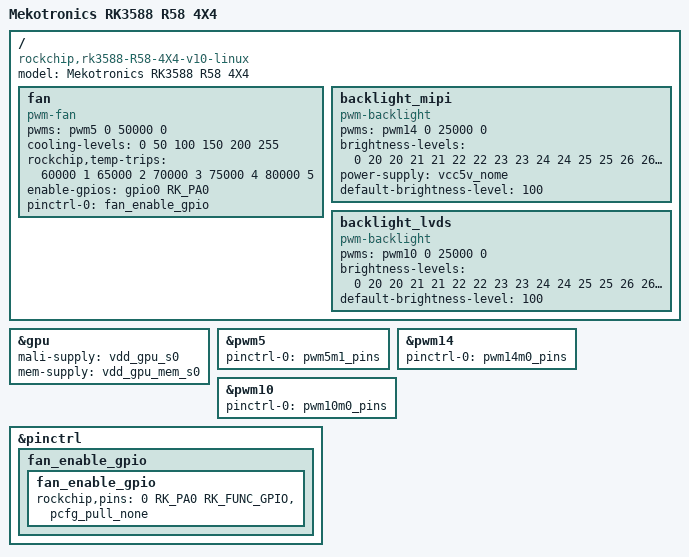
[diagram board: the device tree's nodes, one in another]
// SPDX-License-Identifier: (GPL-2.0+ OR MIT)
/*
 * Copyright (c) 2021 Rockchip Electronics Co., Ltd.
 *
 */

/dts-v1/;

#include "rk3588-blueberry-r58-4X4.dtsi"
#include "rk3588-linux.dtsi"
#include "rk3588-blueberry-r58-4X4-LT6911UXE-1.dtsi"
#include "rk3588-blueberry-r58-4X4-LT6911UXE-2.dtsi"
#include "rk3588-blueberry-r58-4X4-LT6911UXE-3.dtsi"

/ {
	model = "Mekotronics RK3588 R58 4X4";
	compatible = "rockchip,rk3588-R58-4X4-v10-linux", "rockchip,rk3588";
	/delete-node/ chosen;

	fan{
		compatible = "pwm-fan";
		#cooling-cells = <2>;
		pwms = <&pwm5 0 50000 0>;
		cooling-levels = <0 50 100 150 200 255>;
		rockchip,temp-trips = <
				60000	1
				65000	2
				70000	3
				75000	4
				80000	5
		>;
		enable-gpios = <&gpio0 RK_PA0 GPIO_ACTIVE_HIGH>;
		pinctrl-names = "default";
		pinctrl-0 = <&fan_enable_gpio>;
	};

	backlight_mipi: backlight_mipi {
		compatible = "pwm-backlight";
		pwms = <&pwm14 0 25000 0>;
		brightness-levels = <
			  0  20  20  21  21  22  22  23
			 23  24  24  25  25  26  26  27
			 27  28  28  29  29  30  30  31
			 31  32  32  33  33  34  34  35
			 35  36  36  37  37  38  38  39
			 40  41  42  43  44  45  46  47
			 48  49  50  51  52  53  54  55
			 56  57  58  59  60  61  62  63
			 64  65  66  67  68  69  70  71
			 72  73  74  75  76  77  78  79
			 80  81  82  83  84  85  86  87
			 88  89  90  91  92  93  94  95
			 96  97  98  99 100 101 102 103
			104 105 106 107 108 109 110 111
			112 113 114 115 116 117 118 119
			120 121 122 123 124 125 126 127
			128 129 130 131 132 133 134 135
			136 137 138 139 140 141 142 143
			144 145 146 147 148 149 150 151
			152 153 154 155 156 157 158 159
			160 161 162 163 164 165 166 167
			168 169 170 171 172 173 174 175
			176 177 178 179 180 181 182 183
			184 185 186 187 188 189 190 191
			192 193 194 195 196 197 198 199
			200 201 202 203 204 205 206 207
			208 209 210 211 212 213 214 215
			216 217 218 219 220 221 222 223
			224 225 226 227 228 229 230 231
			232 233 234 235 236 237 238 239
			240 241 242 243 244 245 246 247
			248 249 250 251 252 253 254 255
		>;
		power-supply = <&vcc5v_nome>;
		default-brightness-level = <100>;
	};

	backlight_lvds: backlight_lvds {
		compatible = "pwm-backlight";
		pwms = <&pwm10 0 25000 0>;
		brightness-levels = <
			  0  20  20  21  21  22  22  23
			 23  24  24  25  25  26  26  27
			 27  28  28  29  29  30  30  31
			 31  32  32  33  33  34  34  35
			 35  36  36  37  37  38  38  39
			 40  41  42  43  44  45  46  47
			 48  49  50  51  52  53  54  55
			 56  57  58  59  60  61  62  63
			 64  65  66  67  68  69  70  71
			 72  73  74  75  76  77  78  79
			 80  81  82  83  84  85  86  87
			 88  89  90  91  92  93  94  95
			 96  97  98  99 100 101 102 103
			104 105 106 107 108 109 110 111
			112 113 114 115 116 117 118 119
			120 121 122 123 124 125 126 127
			128 129 130 131 132 133 134 135
			136 137 138 139 140 141 142 143
			144 145 146 147 148 149 150 151
			152 153 154 155 156 157 158 159
			160 161 162 163 164 165 166 167
			168 169 170 171 172 173 174 175
			176 177 178 179 180 181 182 183
			184 185 186 187 188 189 190 191
			192 193 194 195 196 197 198 199
			200 201 202 203 204 205 206 207
			208 209 210 211 212 213 214 215
			216 217 218 219 220 221 222 223
			224 225 226 227 228 229 230 231
			232 233 234 235 236 237 238 239
			240 241 242 243 244 245 246 247
			248 249 250 251 252 253 254 255
		>;
		//power-supply = <&vcc5v_nome>;
		default-brightness-level = <100>;
	};

};

&gpu {
	status = "okay";
	mali-supply = <&vdd_gpu_s0>;
	mem-supply = <&vdd_gpu_mem_s0>;
};

&pwm5 {
	pinctrl-0 = <&pwm5m1_pins>;
	status = "okay";
};

&pwm14 {
	pinctrl-0 = <&pwm14m0_pins>;
	status = "okay";
};

&pwm10 {
	pinctrl-0 = <&pwm10m0_pins>;
	status = "okay";
};

&pinctrl {
	fan_enable_gpio {
		fan_enable_gpio: fan_enable_gpio{
			rockchip,pins =
				<0 RK_PA0 RK_FUNC_GPIO &pcfg_pull_none>;
		};
	};
};
